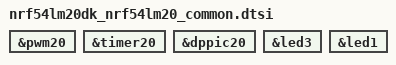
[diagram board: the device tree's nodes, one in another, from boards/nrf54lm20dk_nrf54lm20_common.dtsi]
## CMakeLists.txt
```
# SPDX-License-Identifier: LicenseRef-Nordic-5-Clause

cmake_minimum_required(VERSION 3.20.0)

find_package(Zephyr REQUIRED HINTS $ENV{ZEPHYR_BASE})
project(pwm_events)

target_sources(app PRIVATE src/main.c)
```

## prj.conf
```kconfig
CONFIG_NRFX_PWM=y
CONFIG_NRFX_TIMER=y
CONFIG_NRFX_GPPI=y

CONFIG_ZTEST=y
```

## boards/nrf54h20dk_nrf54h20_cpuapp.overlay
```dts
/*
 * Copyright (c) 2025 Nordic Semiconductor ASA
 *
 * SPDX-License-Identifier: LicenseRef-Nordic-5-Clause
 */

dut_pwm: &pwm130 {
	status = "okay";
};

tst_timer: &timer131 {
	status = "okay";
};

pwm_led: &led3 {
	status = "okay";
};

debug_pin: &led1 {
	status = "okay";
};
```

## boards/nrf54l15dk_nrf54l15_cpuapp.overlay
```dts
/*
 * Copyright (c) 2025 Nordic Semiconductor ASA
 *
 * SPDX-License-Identifier: LicenseRef-Nordic-5-Clause
 */

dut_pwm: &pwm20 {
	status = "okay";
};

tst_timer: &timer20 {
	status = "okay";
};

&dppic20 {
	status = "okay";
};

pwm_led: &led2 {
	status = "okay";
};
```

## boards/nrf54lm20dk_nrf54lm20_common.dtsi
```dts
/*
 * Copyright (c) 2026 Nordic Semiconductor ASA
 *
 * SPDX-License-Identifier: LicenseRef-Nordic-5-Clause
 */

dut_pwm: &pwm20 {
	status = "okay";
};

tst_timer: &timer20 {
	status = "okay";
};

&dppic20 {
	status = "okay";
};

pwm_led: &led3 {
	status = "okay";
};

debug_pin: &led1 {
	status = "okay";
};
```

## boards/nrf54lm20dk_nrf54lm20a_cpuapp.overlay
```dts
/*
 * Copyright (c) 2025 Nordic Semiconductor ASA
 *
 * SPDX-License-Identifier: LicenseRef-Nordic-5-Clause
 */

dut_pwm: &pwm20 {
	status = "okay";
};

tst_timer: &timer20 {
	status = "okay";
};

&dppic20 {
	status = "okay";
};
```

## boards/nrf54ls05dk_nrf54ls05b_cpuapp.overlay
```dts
/*
 * Copyright (c) 2025 Nordic Semiconductor ASA
 *
 * SPDX-License-Identifier: LicenseRef-Nordic-5-Clause
 */

dut_pwm: &pwm20 {
	status = "okay";
};

tst_timer: &timer20 {
	status = "okay";
};

&dppic20 {
	status = "okay";
};

pwm_led: &led0 {
	status = "okay";
};

debug_pin: &led1 {
	status = "okay";
};
```

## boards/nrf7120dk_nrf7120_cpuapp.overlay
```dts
/*
 * Copyright (c) 2026 Nordic Semiconductor ASA
 *
 * SPDX-License-Identifier: LicenseRef-Nordic-5-Clause
 */

dut_pwm: &pwm20 {
	status = "okay";
};

tst_timer: &timer20 {
	status = "okay";
};

pwm_led: &led3 {
	status = "okay";
};

debug_pin: &led1 {
	status = "okay";
};
```

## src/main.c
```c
/*
 * Copyright (c) 2025, Nordic Semiconductor ASA
 *
 * SPDX-License-Identifier: LicenseRef-Nordic-5-Clause
 */

#include <zephyr/kernel.h>
#include <zephyr/ztest.h>
#include <dmm.h>
#include <nrfx_pwm.h>
#include <nrfx_timer.h>
#include <helpers/nrfx_gppi.h>
#include <debug/ppi_trace.h>

#define PWM_OUTPUT_PIN NRF_DT_GPIOS_TO_PSEL(DT_NODELABEL(pwm_led), gpios)
#define PWM_MEM_SECTION DMM_MEMORY_SECTION(DT_NODELABEL(dut_pwm))

#if defined(CONFIG_PPI_TRACE)
#define DEBUG_PIN NRF_DT_GPIOS_TO_PSEL(DT_NODELABEL(debug_pin), gpios)
#endif

#define SLEEP_TIME_MS 500
#define DUTY_CYCLE_VAL_COUNT 4

struct pwm_events_fixture {
	nrfx_pwm_t *pwm;
	nrf_pwm_sequence_t *pwm_sequence;
	nrfx_timer_t *test_timer;
	uint32_t timer_task_address;
	nrfx_gppi_handle_t gppi_handle;
};

static void configure_pwm(nrfx_pwm_t *pwm)
{
	nrfx_pwm_config_t pwm_config =
		NRFX_PWM_DEFAULT_CONFIG(PWM_OUTPUT_PIN, NRF_PWM_PIN_NOT_CONNECTED,
					NRF_PWM_PIN_NOT_CONNECTED, NRF_PWM_PIN_NOT_CONNECTED);

	pwm_config.count_mode = NRF_PWM_MODE_UP_AND_DOWN;
	pwm_config.top_value = 0x1000;

	zassert_ok(nrfx_pwm_init(pwm, &pwm_config, NULL, NULL), "NRFX PWM init failed\n");
}

static uint32_t configure_test_timer(nrfx_timer_t *timer)
{
	uint32_t base_frequency = NRF_TIMER_BASE_FREQUENCY_GET(timer->p_reg);
	nrfx_timer_config_t timer_config = NRFX_TIMER_DEFAULT_CONFIG(base_frequency);

	timer_config.bit_width = NRF_TIMER_BIT_WIDTH_16;
	timer_config.mode = NRF_TIMER_MODE_COUNTER;

	TC_PRINT("Timer base frequency: %d Hz\n", base_frequency);

	zassert_ok(nrfx_timer_init(timer, &timer_config, NULL), "Timer init failed\n");
	nrfx_timer_enable(timer);

	return nrfx_timer_task_address_get(timer, NRF_TIMER_TASK_COUNT);
}

static void setup_dppi_connection(nrfx_gppi_handle_t *gppi_handle, uint32_t timer_task_address,
				  uint32_t pwm_event_address)
{
	zassert_ok(nrfx_gppi_conn_alloc(pwm_event_address, timer_task_address, gppi_handle),
		   "Failed to allocate DPPI connection\n");
	nrfx_gppi_conn_enable(*gppi_handle);
}

static void clear_dppi_connection(nrfx_gppi_handle_t *gppi_handle, uint32_t timer_task_address,
				  uint32_t pwm_event_address)
{
	nrfx_gppi_conn_disable(*gppi_handle);
	nrfx_gppi_conn_free(pwm_event_address, timer_task_address, *gppi_handle);
}

static void run_pwm_event_test_case(struct pwm_events_fixture *fixture,
				    nrf_pwm_event_t tested_pwm_event,
				    uint32_t expected_triggers_count, char *event_name)
{
	uint32_t pwm_event_address;
	uint32_t timer_cc_before, timer_cc_after;

#if defined(CONFIG_PPI_TRACE)
	void *handle;
#endif

	pwm_event_address = nrf_pwm_event_address_get(fixture->pwm->p_reg, tested_pwm_event);
	setup_dppi_connection(&fixture->gppi_handle, fixture->timer_task_address,
			      pwm_event_address);
	nrf_pwm_event_clear(fixture->pwm->p_reg, tested_pwm_event);

#if defined(CONFIG_PPI_TRACE)
	/*
	 * Note that configuring PPI trace
	 * will break DPPI connection to the timer.
	 * Timer will not count events
	 */
	handle = ppi_trace_config(DEBUG_PIN, pwm_event_address);
	zassert_not_null(handle, "PPI trace configuration failed\n");
	ppi_trace_enable(handle);
#endif

	timer_cc_before = nrfx_timer_capture(fixture->test_timer, NRF_TIMER_CC_CHANNEL0);
	nrfx_pwm_simple_playback(fixture->pwm, fixture->pwm_sequence, 1, NRFX_PWM_FLAG_STOP);
	k_msleep(SLEEP_TIME_MS);
	timer_cc_after = nrfx_timer_capture(fixture->test_timer, NRF_TIMER_CC_CHANNEL0);

	TC_PRINT("PWM %s events count: %d\n", event_name, timer_cc_after - timer_cc_before);
	zassert_equal(timer_cc_after - timer_cc_before, expected_triggers_count,
		      "PWM %s event triggered count != %u\n", event_name, expected_triggers_count);

	nrf_pwm_event_clear(fixture->pwm->p_reg, tested_pwm_event);
	clear_dppi_connection(&fixture->gppi_handle, fixture->timer_task_address,
			      pwm_event_address);

#if defined(CONFIG_PPI_TRACE)
	ppi_trace_disable(handle);
#endif
}

ZTEST_F(pwm_events, test_pwm_stop_event)
{
	run_pwm_event_test_case(fixture, NRF_PWM_EVENT_STOPPED, 1, "STOP");
}

ZTEST_F(pwm_events, test_pwm_seqstarted_event)
{
	run_pwm_event_test_case(fixture, NRF_PWM_EVENT_SEQSTARTED1, 1, "SEQSTARTED1");
}

ZTEST_F(pwm_events, test_pwm_seqend_event)
{
	run_pwm_event_test_case(fixture, NRF_PWM_EVENT_SEQEND1, 1, "SEQEND1");
}

ZTEST_F(pwm_events, test_pwm_periodend_event)
{
	run_pwm_event_test_case(fixture, NRF_PWM_EVENT_PWMPERIODEND, fixture->pwm_sequence->length,
				"PWMPERIODEND");
}

ZTEST_F(pwm_events, test_pwm_loopsdone_event)
{
	run_pwm_event_test_case(fixture, NRF_PWM_EVENT_LOOPSDONE, 1, "LOOPSDONE");
}

ZTEST_F(pwm_events, test_pwm_comparematch_event)
{
	run_pwm_event_test_case(fixture, offsetof(NRF_PWM_Type, EVENTS_COMPAREMATCH[0]),
				fixture->pwm_sequence->length * 2, "COMPAREMATCH");
}

/*
 * MLTPAN-115/HMPAN-235 related test
 * PAN symptoms:
 * EVENT_COMPAREMATCH toggles before EVENT_STARTED/SEQSTARTED
 *
 * This test case uses two GPPI routes:
 * PWM COMPAREMATCH EVENT -> TIMER TASK_COUNT
 * PWM SEQSTARTED EVENT -> TIMER TASK_STOP
 *
 * It is routed like this to count the PWM COMPAREMATCH events
 * triggered before PWM SEQSTARTED event triggers
 *
 * PPI trace is not available for this test
 */
ZTEST_F(pwm_events, test_pwm_comparematch_and_seqstared_events)
{
	uint32_t comparematch_pwm_event_address, seqstared_pwm_event_address;
	uint32_t timer_cc_before, timer_cc_after;
	uint32_t timer_stop_task_address;
	nrf_pwm_event_t comparematch_pwm_event = offsetof(NRF_PWM_Type, EVENTS_COMPAREMATCH[0]);
	nrf_pwm_event_t seqstarted_pwm_event = NRF_PWM_EVENT_SEQSTARTED1;
	nrfx_gppi_handle_t second_gppi_handle;

	comparematch_pwm_event_address =
		nrf_pwm_event_address_get(fixture->pwm->p_reg, comparematch_pwm_event);
	setup_dppi_connection(&fixture->gppi_handle, fixture->timer_task_address,
			      comparematch_pwm_event_address);
	nrf_pwm_event_clear(fixture->pwm->p_reg, comparematch_pwm_event);

	timer_stop_task_address =
		nrfx_timer_task_address_get(fixture->test_timer, NRF_TIMER_TASK_STOP);
	seqstared_pwm_event_address =
		nrf_pwm_event_address_get(fixture->pwm->p_reg, seqstarted_pwm_event);
	setup_dppi_connection(&second_gppi_handle, timer_stop_task_address,
			      seqstared_pwm_event_address);
	nrf_pwm_event_clear(fixture->pwm->p_reg, seqstarted_pwm_event);

	timer_cc_before = nrfx_timer_capture(fixture->test_timer, NRF_TIMER_CC_CHANNEL0);
	nrfx_pwm_simple_playback(fixture->pwm, fixture->pwm_sequence, 1, NRFX_PWM_FLAG_STOP);
	k_msleep(SLEEP_TIME_MS);
	timer_cc_after = nrfx_timer_capture(fixture->test_timer, NRF_TIMER_CC_CHANNEL0);

	nrf_pwm_event_clear(fixture->pwm->p_reg, comparematch_pwm_event);
	nrf_pwm_event_clear(fixture->pwm->p_reg, seqstarted_pwm_event);

	clear_dppi_connection(&fixture->gppi_handle, fixture->timer_task_address,
			      comparematch_pwm_event_address);
	clear_dppi_connection(&second_gppi_handle, timer_stop_task_address,
			      seqstared_pwm_event_address);

	/*
	 * restart timer
	 * timer was disabled by the STOP_TASK through GPPI
	 */
	nrfx_timer_disable(fixture->test_timer);
	nrfx_timer_enable(fixture->test_timer);

	TC_PRINT(
		"PWM EVENTS_COMPAREMATCH events count before NRF_PWM_EVENT_SEQSTARTED1 event: %d\n",
		timer_cc_after - timer_cc_before);
	zassert_equal(timer_cc_after - timer_cc_before, 0,
		      "EVENTS_COMPAREMATCH should not trigger before NRF_PWM_EVENT_SEQSTARTED1");
}

static void *test_setup(void)
{
	static struct pwm_events_fixture fixture;
	static nrfx_timer_t test_timer = NRFX_TIMER_INSTANCE(DT_REG_ADDR(DT_NODELABEL(tst_timer)));
	static nrfx_pwm_t pwm = NRFX_PWM_INSTANCE(DT_REG_ADDR(DT_NODELABEL(dut_pwm)));
	static nrf_pwm_values_common_t pwm_duty_cycle_values[DUTY_CYCLE_VAL_COUNT] PWM_MEM_SECTION;
	static nrf_pwm_sequence_t pwm_sequence = {.values = {pwm_duty_cycle_values},
						  .length = ARRAY_SIZE(pwm_duty_cycle_values),
						  .repeats = 0,
						  .end_delay = 0};

	/* Startup code does not initialize variables placed in special memory regions. */
	for (size_t i = 0; i < ARRAY_SIZE(pwm_duty_cycle_values); i++) {
		pwm_duty_cycle_values[i] = (i & 0x01) ? 0x0500 : 0x0600;
	}

	fixture.pwm = &pwm;
	fixture.pwm_sequence = &pwm_sequence;
	configure_pwm(&pwm);

	fixture.test_timer = &test_timer;
	fixture.timer_task_address = configure_test_timer(&test_timer);

	return &fixture;
}

ZTEST_SUITE(pwm_events, NULL, test_setup, NULL, NULL, NULL);
```
